AUTOSAR XML (schema 4-0-3)
package /ComponentTypes
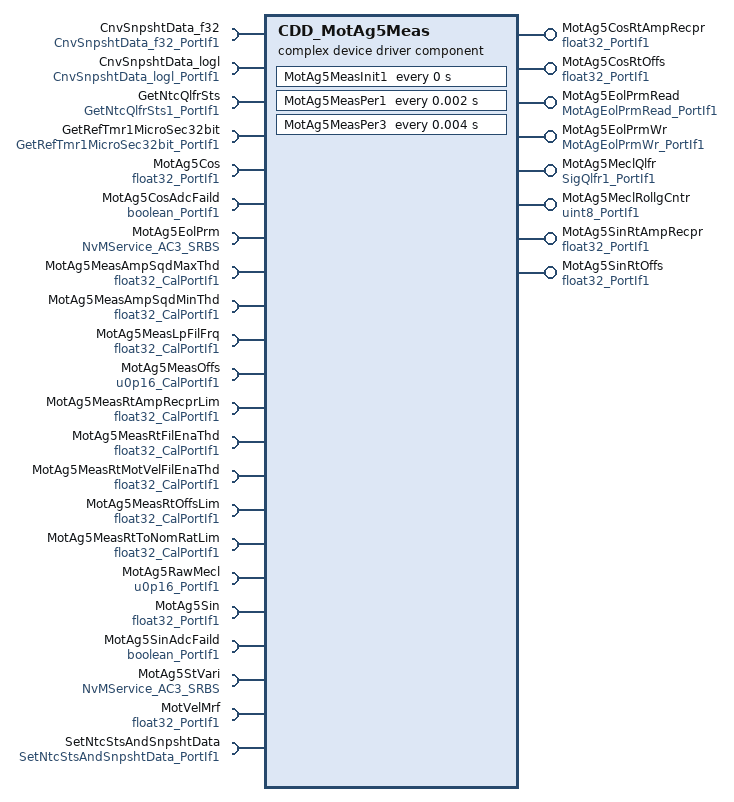
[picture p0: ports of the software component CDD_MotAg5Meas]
  complex device driver sw component type CDD_MotAg5Meas
    8 x provide port:
      MotAg5CosRtAmpRecpr: nonqueued-sender-com-spec{data-element=Val, init-value=1}, provided-interface=float32_PortIf1
      MotAg5CosRtOffs: nonqueued-sender-com-spec{data-element=Val, init-value=2.5}, provided-interface=float32_PortIf1
      MotAg5EolPrmRead: server-com-spec{operation=Oper, queue-length=1}, provided-interface=MotAgEolPrmRead_PortIf1
      MotAg5EolPrmWr: server-com-spec{operation=Oper, queue-length=1}, provided-interface=MotAgEolPrmWr_PortIf1
      MotAg5MeclQlfr: nonqueued-sender-com-spec{data-element=Val, init-value=0}, provided-interface=SigQlfr1_PortIf1
      MotAg5MeclRollgCntr: nonqueued-sender-com-spec{data-element=Val, init-value=0}, provided-interface=uint8_PortIf1
      MotAg5SinRtAmpRecpr: nonqueued-sender-com-spec{data-element=Val, init-value=1}, provided-interface=float32_PortIf1
      MotAg5SinRtOffs: nonqueued-sender-com-spec{data-element=Val, init-value=2.5}, provided-interface=float32_PortIf1
    22 x require port:
      CnvSnpshtData_f32: client-com-spec=Oper, required-interface=CnvSnpshtData_f32_PortIf1
      CnvSnpshtData_logl: client-com-spec=Oper, required-interface=CnvSnpshtData_logl_PortIf1
      GetNtcQlfrSts: client-com-spec=Oper, required-interface=GetNtcQlfrSts1_PortIf1
      GetRefTmr1MicroSec32bit: client-com-spec=Oper, required-interface=GetRefTmr1MicroSec32bit_PortIf1
      MotAg5Cos: nonqueued-receiver-com-spec{data-element=Val, filter=data-filter-type=ALWAYS, init-value=1.65}, required-interface=float32_PortIf1
      MotAg5CosAdcFaild: nonqueued-receiver-com-spec{data-element=Logl, filter=data-filter-type=ALWAYS, init-value=0}, required-interface=boolean_PortIf1
      MotAg5EolPrm: required-com-specs=[EraseBlock, GetErrorStatus, InvalidateNvBlock, ReadBlock, SetRamBlockStatus, WriteBlock], required-interface=NvMService_AC3_SRBS
      MotAg5MeasAmpSqdMaxThd: parameter-require-com-spec{init-value=2.8, parameter=Val}, required-interface=float32_CalPortIf1
      MotAg5MeasAmpSqdMinThd: parameter-require-com-spec{init-value=0.0625, parameter=Val}, required-interface=float32_CalPortIf1
      MotAg5MeasLpFilFrq: parameter-require-com-spec{init-value=0.1, parameter=Val}, required-interface=float32_CalPortIf1
      MotAg5MeasOffs: parameter-require-com-spec{init-value=0, parameter=Val}, required-interface=u0p16_CalPortIf1
      MotAg5MeasRtAmpRecprLim: parameter-require-com-spec{init-value=0.122, parameter=Val}, required-interface=float32_CalPortIf1
      MotAg5MeasRtFilEnaThd: parameter-require-com-spec{init-value=0.99, parameter=Val}, required-interface=float32_CalPortIf1
      MotAg5MeasRtMotVelFilEnaThd: parameter-require-com-spec{init-value=100, parameter=Val}, required-interface=float32_CalPortIf1
      MotAg5MeasRtOffsLim: parameter-require-com-spec{init-value=0.1, parameter=Val}, required-interface=float32_CalPortIf1
      MotAg5MeasRtToNomRatLim: parameter-require-com-spec{init-value=0.1, parameter=Val}, required-interface=float32_CalPortIf1
      MotAg5RawMecl: nonqueued-receiver-com-spec{data-element=Val, filter=data-filter-type=ALWAYS, init-value=0}, required-interface=u0p16_PortIf1
      MotAg5Sin: nonqueued-receiver-com-spec{data-element=Val, filter=data-filter-type=ALWAYS, init-value=1.65}, required-interface=float32_PortIf1
      MotAg5SinAdcFaild: nonqueued-receiver-com-spec{data-element=Logl, filter=data-filter-type=ALWAYS, init-value=0}, required-interface=boolean_PortIf1
      MotAg5StVari: required-com-specs=[EraseBlock, GetErrorStatus, InvalidateNvBlock, ReadBlock, SetRamBlockStatus, WriteBlock], required-interface=NvMService_AC3_SRBS
      MotVelMrf: nonqueued-receiver-com-spec{data-element=Val, filter=data-filter-type=ALWAYS, init-value=0}, required-interface=float32_PortIf1
      SetNtcStsAndSnpshtData: client-com-spec=Oper, required-interface=SetNtcStsAndSnpshtData_PortIf1
    behavior CDD_MotAg5Meas_InternalBehavior
      ar-typed-per-instance-memorys:
        11 x data, all with sw-calibration-access=READ-ONLY:
          dMotAg5MeasAmpVal: type=float32
          MotAg5CosMaxLpFil: type=FilLpRec1
          MotAg5CosMinLpFil: type=FilLpRec1
          MotAg5EolPrm: type=MotAgEolPrmRec1
          MotAg5NvmFltEna: type=boolean
          MotAg5PrevRollgCntr: type=uint8
          MotAg5RtPrm: type=MotAgRtPrmRec1
          MotAg5SinMaxLpFil: type=FilLpRec1
          MotAg5SinMinLpFil: type=FilLpRec1
          MotAg5StVari: type=MotAgStVariRec1
          PrevMotAg5Mecl: type=u0p16
      operation invoked event OIT_MotAg5EolPrmRead_Oper_MotAg5EolPrmRead_Oper: start-on-event=MotAg5EolPrmRead_Oper, operation=MotAg5EolPrmRead.Oper
      operation invoked event OIT_MotAg5EolPrmWr_Oper_MotAg5EolPrmWr_Oper: start-on-event=MotAg5EolPrmWr_Oper, operation=MotAg5EolPrmWr.Oper
      timing event MotAg5Meas_InitEvent: start-on-event=MotAg5MeasInit1, period=0
      timing event TMT_MotAg5MeasPer1: start-on-event=MotAg5MeasPer1, period=0.002
      timing event TMT_MotAg5MeasPer3: start-on-event=MotAg5MeasPer3, period=0.004
      explicit-inter-runnable-variables:
        data MotAg5PrtclOk: type=boolean, init-value=0
        data MotAg5RtVari: type=MotAgRtPrmRec1, init-value=fields=[SinRtOffs:2.5, SinRtAmpRecpr:1, CosRtOffs:2.5, CosRtAmpRecpr:1, SinGainCorrd:1, CosGainCorrd:1, SinOffsCorrd:0, CosOffsCorrd:0, CosSinNomRatio:1, SinCosNomRatio:1, RtToNomRatioLoLim:1, RtToNomRatioHiLim:1, PrevSinRtOffs:2.5, PrevCosRtOffs:2.5]
      5 x runnable:
        MotAg5EolPrmRead_Oper
        MotAg5EolPrmWr_Oper
          sync call SC_MotAg5EolPrm_SetRamBlockStatus: operation=MotAg5EolPrm.SetRamBlockStatus, timeout=0
        MotAg5MeasInit1
          sync call SC_MotAg5EolPrm_GetErrorStatus: operation=MotAg5EolPrm.GetErrorStatus, timeout=0
          sync call SC_MotAg5StVari_GetErrorStatus: operation=MotAg5StVari.GetErrorStatus, timeout=0
        MotAg5MeasPer1
          data-receive-point-by-arguments:
            4 x access:
              REC_MotAg5Cos_Val: accessed-variable=MotAg5Cos.Val
              REC_MotAg5CosAdcFaild_Logl: accessed-variable=MotAg5CosAdcFaild.Logl
              REC_MotAg5Sin_Val: accessed-variable=MotAg5Sin.Val
              REC_MotAg5SinAdcFaild_Logl: accessed-variable=MotAg5SinAdcFaild.Logl
          data-send-points:
            6 x access:
              SEND_MotAg5CosRtAmpRecpr_Val: accessed-variable=MotAg5CosRtAmpRecpr.Val
              SEND_MotAg5CosRtOffs_Val: accessed-variable=MotAg5CosRtOffs.Val
              SEND_MotAg5Qlfr_Val: accessed-variable=MotAg5MeclQlfr.Val
              SEND_MotAg5RollgCntr_Val: accessed-variable=MotAg5MeclRollgCntr.Val
              SEND_MotAg5SinRtAmpRecpr_Val: accessed-variable=MotAg5SinRtAmpRecpr.Val
              SEND_MotAg5SinRtOffs_Val: accessed-variable=MotAg5SinRtOffs.Val
          read-local-variables:
            access READ_MotAg5RtVari: accessed-variable=MotAg5RtVari
          4 x sync call, all with timeout=0:
            SC_CnvSnpshtData_f32_Oper: operation=CnvSnpshtData_f32.Oper
            SC_CnvSnpshtData_logl_Oper: operation=CnvSnpshtData_logl.Oper
            SC_GetNtcQlfrSts1_Oper: operation=GetNtcQlfrSts.Oper
            SC_SetNtcStsAndSnpshtData_Oper: operation=SetNtcStsAndSnpshtData.Oper
          written-local-variables:
            access WRITE_MotAg5PrtclOk: accessed-variable=MotAg5PrtclOk
        MotAg5MeasPer3
          data-receive-point-by-arguments:
            4 x access:
              REC_MotAg5Cos_Val: accessed-variable=MotAg5Cos.Val
              REC_MotAg5RawMecl_Val: accessed-variable=MotAg5RawMecl.Val
              REC_MotAg5Sin_Val: accessed-variable=MotAg5Sin.Val
              REC_MotVelMrf_Val: accessed-variable=MotVelMrf.Val
          read-local-variables:
            access READ_MotAg5PrtclOk: accessed-variable=MotAg5PrtclOk
          sync call SC_MotAg5StVari_SetRamBlockStatus: operation=MotAg5StVari.SetRamBlockStatus, timeout=0
          written-local-variables:
            access WRITE_MotAg5RtVari: accessed-variable=MotAg5RtVari
      swc service dependency MotAg5EolPrmNvm: assigned-datas=role-based-data-assignment={role=ramBlock, used-data-element=MotAg5EolPrm}, assigned-ports=role-based-port-assignment={port-prototype=MotAg5EolPrm, role=NvMService_AC3_SRBS}
        service-needs:
          nv block needs MotAg5EolPrmNvm: n-data-sets=0, readonly=false, reliability=ERROR-DETECTION, resistant-to-changed-sw=true, restore-at-start=true, store-at-shutdown=true
      swc service dependency MotAg5StVariNvm: assigned-datas=role-based-data-assignment={role=ramBlock, used-data-element=MotAg5StVari}, assigned-ports=role-based-port-assignment={port-prototype=MotAg5StVari, role=NvMService_AC3_SRBS}
        service-needs:
          nv block needs MotAg5StVariNvm: n-data-sets=0, readonly=false, reliability=ERROR-DETECTION, resistant-to-changed-sw=true, restore-at-start=true, store-at-shutdown=true
  swc implementation CDD_MotAg5Meas_Implementation: behavior=CDD_MotAg5Meas_InternalBehavior
    code-descriptors:
      code Default: artifact-descriptors=autosar-engineering-object={short-label=Default, category=SWSRC}
